AUTOSAR XML (schema 4-0-3)
package /ComponentTypes
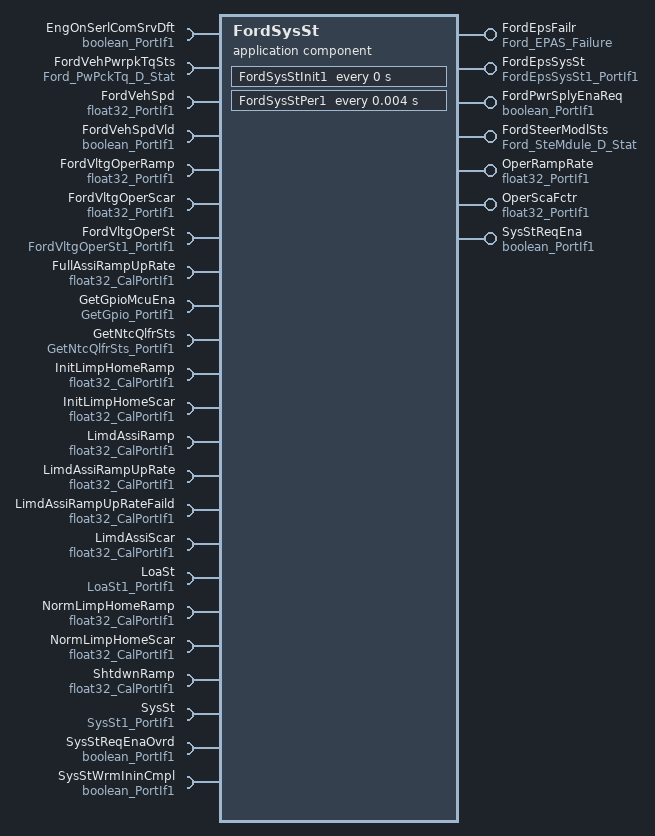
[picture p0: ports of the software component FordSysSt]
  application sw component type FordSysSt
    7 x provide port:
      FordEpsFailr: nonqueued-sender-com-spec{data-element=Ford_EPAS_Failure, init-value=0}, provided-interface=Ford_EPAS_Failure
      FordEpsSysSt: nonqueued-sender-com-spec{data-element=Val, init-value=0}, provided-interface=FordEpsSysSt1_PortIf1
      FordPwrSplyEnaReq: nonqueued-sender-com-spec{data-element=Logl, init-value=0}, provided-interface=boolean_PortIf1
      FordSteerModlSts: nonqueued-sender-com-spec{data-element=Ford_SteMdule_D_Stat, init-value=0}, provided-interface=Ford_SteMdule_D_Stat
      OperRampRate: nonqueued-sender-com-spec{data-element=Val, init-value=50}, provided-interface=float32_PortIf1
      OperScaFctr: nonqueued-sender-com-spec{data-element=Val, init-value=1}, provided-interface=float32_PortIf1
      SysStReqEna: nonqueued-sender-com-spec{data-element=Logl, init-value=0}, provided-interface=boolean_PortIf1
    23 x require port:
      EngOnSerlComSrvDft: nonqueued-receiver-com-spec{data-element=Logl, filter=data-filter-type=ALWAYS, init-value=0}, required-interface=boolean_PortIf1
      FordVehPwrpkTqSts: nonqueued-receiver-com-spec{data-element=Ford_PwPckTq_D_Stat, filter=data-filter-type=ALWAYS, init-value=0}, required-interface=Ford_PwPckTq_D_Stat
      FordVehSpd: nonqueued-receiver-com-spec{data-element=Val, filter=data-filter-type=ALWAYS, init-value=0}, required-interface=float32_PortIf1
      FordVehSpdVld: nonqueued-receiver-com-spec{data-element=Logl, filter=data-filter-type=ALWAYS, init-value=0}, required-interface=boolean_PortIf1
      FordVltgOperRamp: nonqueued-receiver-com-spec{data-element=Val, filter=data-filter-type=ALWAYS, init-value=1.0}, required-interface=float32_PortIf1
      FordVltgOperScar: nonqueued-receiver-com-spec{data-element=Val, filter=data-filter-type=ALWAYS, init-value=1}, required-interface=float32_PortIf1
      FordVltgOperSt: nonqueued-receiver-com-spec{data-element=Val, filter=data-filter-type=ALWAYS, init-value=0}, required-interface=FordVltgOperSt1_PortIf1
      FullAssiRampUpRate: parameter-require-com-spec{init-value=1, parameter=Val}, required-interface=float32_CalPortIf1
      GetGpioMcuEna: client-com-spec=Oper, required-interface=GetGpio_PortIf1
      GetNtcQlfrSts: client-com-spec=Oper, required-interface=GetNtcQlfrSts_PortIf1
      InitLimpHomeRamp: parameter-require-com-spec{init-value=1, parameter=Val}, required-interface=float32_CalPortIf1
      InitLimpHomeScar: parameter-require-com-spec{init-value=0, parameter=Val}, required-interface=float32_CalPortIf1
      LimdAssiRamp: parameter-require-com-spec{init-value=1, parameter=Val}, required-interface=float32_CalPortIf1
      LimdAssiRampUpRate: parameter-require-com-spec{init-value=1, parameter=Val}, required-interface=float32_CalPortIf1
      LimdAssiRampUpRateFaild: parameter-require-com-spec{init-value=1, parameter=Val}, required-interface=float32_CalPortIf1
      LimdAssiScar: parameter-require-com-spec{init-value=0, parameter=Val}, required-interface=float32_CalPortIf1
      LoaSt: nonqueued-receiver-com-spec{data-element=Val, filter=data-filter-type=ALWAYS, init-value=0}, required-interface=LoaSt1_PortIf1
      NormLimpHomeRamp: parameter-require-com-spec{init-value=1, parameter=Val}, required-interface=float32_CalPortIf1
      NormLimpHomeScar: parameter-require-com-spec{init-value=0, parameter=Val}, required-interface=float32_CalPortIf1
      ShtdwnRamp: parameter-require-com-spec{init-value=1, parameter=Val}, required-interface=float32_CalPortIf1
      SysSt: nonqueued-receiver-com-spec{data-element=Val, filter=data-filter-type=ALWAYS, init-value=3}, required-interface=SysSt1_PortIf1
      SysStReqEnaOvrd: nonqueued-receiver-com-spec{data-element=Logl, filter=data-filter-type=ALWAYS, init-value=0}, required-interface=boolean_PortIf1
      SysStWrmIninCmpl: nonqueued-receiver-com-spec{data-element=Logl, filter=data-filter-type=ALWAYS, init-value=0}, required-interface=boolean_PortIf1
    behavior FordSysSt_InternalBehavior
      exclusive area FordSysStExclusiveArea
      ar-typed-per-instance-memorys:
        8 x data, all with sw-calibration-access=READ-ONLY:
          FordEpsFailrPrev: type=Ford_EPAS_Failure
          FordEpsSysStPrev: type=FordEpsSysSt1
          FordSteerModlStsPrev: type=Ford_SteMdule_D_Stat
          FordVltgOperRamp: type=float32
          FordVltgOperScar: type=float32
          OperRampRatePrev: type=float32
          OperScaFctrPrev: type=float32
          SysStReqEnaPrev: type=boolean
      timing event FordSysStInit1_InitEvent: start-on-event=FordSysStInit1, period=0
      timing event TMT_FordSysStPer1: start-on-event=FordSysStPer1, period=0.004
      port-api-options:
        enable-take-address=false, indirect-api=false, port=EngOnSerlComSrvDft
        enable-take-address=false, indirect-api=false, port=FordEpsFailr
        enable-take-address=false, indirect-api=false, port=FordEpsSysSt
        enable-take-address=false, indirect-api=false, port=FordPwrSplyEnaReq
        enable-take-address=false, indirect-api=false, port=FordSteerModlSts
        enable-take-address=false, indirect-api=false, port=FordVehPwrpkTqSts
        enable-take-address=false, indirect-api=false, port=FordVehSpd
        enable-take-address=false, indirect-api=false, port=FordVehSpdVld
        enable-take-address=false, indirect-api=false, port=FordVltgOperRamp
        enable-take-address=false, indirect-api=false, port=FordVltgOperScar
        enable-take-address=false, indirect-api=false, port=FordVltgOperSt
        enable-take-address=false, indirect-api=false, port=FullAssiRampUpRate
        enable-take-address=false, indirect-api=false, port=GetGpioMcuEna
        enable-take-address=false, indirect-api=false, port=GetNtcQlfrSts
        enable-take-address=false, indirect-api=false, port=InitLimpHomeScar
        enable-take-address=false, indirect-api=false, port=LimdAssiRamp
        enable-take-address=false, indirect-api=false, port=LimdAssiRampUpRate
        enable-take-address=false, indirect-api=false, port=LimdAssiRampUpRateFaild
        enable-take-address=false, indirect-api=false, port=LimdAssiScar
        enable-take-address=false, indirect-api=false, port=LoaSt
        enable-take-address=false, indirect-api=false, port=NormLimpHomeScar
        enable-take-address=false, indirect-api=false, port=OperRampRate
        enable-take-address=false, indirect-api=false, port=OperScaFctr
        enable-take-address=false, indirect-api=false, port=ShtdwnRamp
        enable-take-address=false, indirect-api=false, port=SysSt
        enable-take-address=false, indirect-api=false, port=SysStReqEna
      runnable FordSysStInit1
      runnable FordSysStPer1: can-enter-exclusive-area=FordSysStExclusiveArea
        data-receive-point-by-arguments:
          11 x access:
            REC_EngOnSerlComSrvDft_Logl: accessed-variable=EngOnSerlComSrvDft.Logl
            REC_FordLoaSt_Val: accessed-variable=LoaSt.Val
            REC_FordSysSt_Val: accessed-variable=SysSt.Val
            REC_FordVehPwrpkTqSts_Ford_PwPckTq_D_Stat: accessed-variable=FordVehPwrpkTqSts.Ford_PwPckTq_D_Stat
            REC_FordVehSpd_Val: accessed-variable=FordVehSpd.Val
            REC_FordVehSpdVld_Logl: accessed-variable=FordVehSpdVld.Logl
            REC_FordVltgOperRamp_Val: accessed-variable=FordVltgOperRamp.Val
            REC_FordVltgOperScar_Val: accessed-variable=FordVltgOperScar.Val
            REC_FordVltgOperSt_Val: accessed-variable=FordVltgOperSt.Val
            REC_SysStReqEnaOvrd_Logl: accessed-variable=SysStReqEnaOvrd.Logl
            REC_SysStWrmIninCmpl_Logl: accessed-variable=SysStWrmIninCmpl.Logl
        data-send-points:
          7 x access:
            SEND_FordEpsFailr_Ford_EPAS_Failure: accessed-variable=FordEpsFailr.Ford_EPAS_Failure
            SEND_FordEpsSysSt_Val: accessed-variable=FordEpsSysSt.Val
            SEND_FordPwrSplyEnaReq_Logl: accessed-variable=FordPwrSplyEnaReq.Logl
            SEND_FordSteerModlSts_Ford_SteMdule_D_Stat: accessed-variable=FordSteerModlSts.Ford_SteMdule_D_Stat
            SEND_OperRampRate_Val: accessed-variable=OperRampRate.Val
            SEND_OperScarFctr_Val: accessed-variable=OperScaFctr.Val
            SEND_SysStReqEna_Logl: accessed-variable=SysStReqEna.Logl
        sync call SC_GetGpioMcuEna_Oper: operation=GetGpioMcuEna.Oper, timeout=0
        sync call SC_GetNtcQlfrSts_Oper: operation=GetNtcQlfrSts.Oper, timeout=0
  swc implementation FordSysSt_Implementation: behavior=FordSysSt_InternalBehavior
    code-descriptors:
      code Default: artifact-descriptors=autosar-engineering-object={short-label=Default, category=SWSRC}
